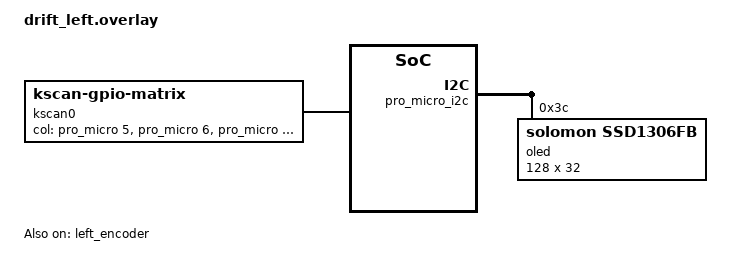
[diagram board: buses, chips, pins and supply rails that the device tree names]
// Copyright (c) 2025 The ZMK Contributors
// SPDX-License-Identifier: MIT

#include "drift.dtsi"

// Enable left encoder device (for volume, scrolling, etc.)
&left_encoder {
	status = "okay";
};

 / {
	chosen {
		// Define the default key scanning matrix
		zmk,kscan = &kscan0;
	};

	// Keyboard matrix definition
	kscan0: kscan {
		compatible = "zmk,kscan-gpio-matrix";		
		diode-direction = "col2row";       // Current flows from column → row
		wakeup-source;                     // Allow wake from sleep on key press

		// Column pins (C0–C6)
		col-gpios = <&pro_micro 5 GPIO_ACTIVE_HIGH>
		           ,<&pro_micro 6 GPIO_ACTIVE_HIGH>
		           ,<&pro_micro 7 GPIO_ACTIVE_HIGH>
		           ,<&pro_micro 8 GPIO_ACTIVE_HIGH>
		           ,<&pro_micro 9 GPIO_ACTIVE_HIGH>
		           ,<&pro_micro 10 GPIO_ACTIVE_HIGH>
		           ,<&pro_micro 16 GPIO_ACTIVE_HIGH>;		
	};
};

&pro_micro_i2c {
    status = "okay";

    oled: ssd1306@3c {
        compatible = "solomon,ssd1306fb";
        reg = <0x3c>;
        width = <128>;
        height = <32>;
        segment-offset = <0>;
        page-offset = <0>;
        display-offset = <0>;
        multiplex-ratio = <31>;
        segment-remap;
        com-invdir;
        com-sequential;
        inversion-on;
        prechargep = <0x22>;
    };
};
